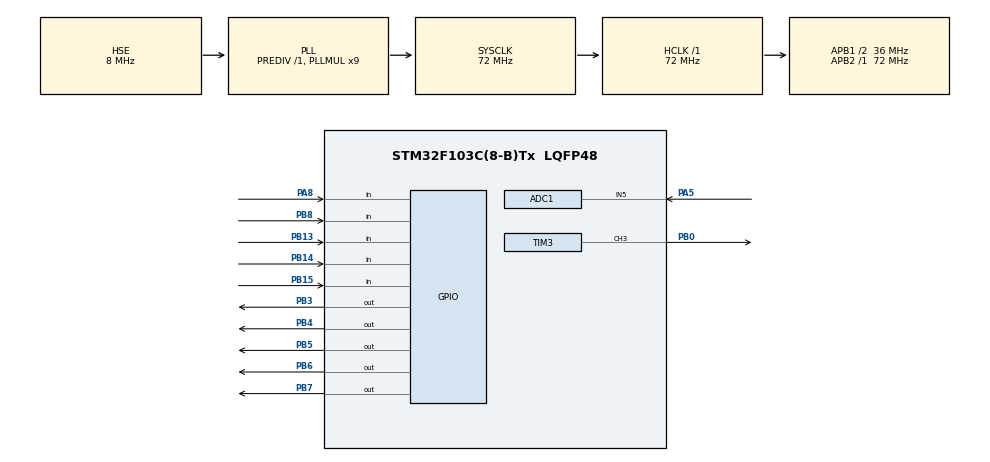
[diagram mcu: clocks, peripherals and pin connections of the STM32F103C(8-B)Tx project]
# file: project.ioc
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ADC1.Channel-0\#ChannelRegularConversion=ADC_CHANNEL_5
ADC1.ContinuousConvMode=ENABLE
ADC1.NbrOfConversionFlag=1
ADC1.Rank-0\#ChannelRegularConversion=1
ADC1.SamplingTime-0\#ChannelRegularConversion=ADC_SAMPLETIME_1CYCLE_5
ADC1.master=1
Mcu.Family=STM32F1
Mcu.Name=STM32F103C(8-B)Tx
Mcu.Package=LQFP48
NVIC.ADC1_2_IRQn=true\:0\:1\:false\:false\:true\:true\:true\:true
NVIC.PriorityGroup=NVIC_PRIORITYGROUP_2
NVIC.RCC_IRQn=true\:0\:0\:false\:false\:true\:true\:false\:true
NVIC.TIM1_UP_IRQn=true\:1\:0\:true\:false\:true\:true\:true\:true
NVIC.TIM2_IRQn=true\:2\:0\:true\:false\:true\:true\:true\:true
PA13.Mode=Serial_Wire
PA13.Signal=SYS_JTMS-SWDIO
PA14.Mode=Serial_Wire
PA14.Signal=SYS_JTCK-SWCLK
PA5.Signal=ADCx_IN5
PA8.GPIO_PuPd=GPIO_PULLUP
PA8.Signal=GPIO_Input
PB0.Signal=S_TIM3_CH3
PB13.GPIO_PuPd=GPIO_PULLUP
PB13.Signal=GPIO_Input
PB14.GPIO_PuPd=GPIO_PULLUP
PB14.Signal=GPIO_Input
PB15.GPIO_PuPd=GPIO_PULLUP
PB15.Signal=GPIO_Input
PB3.GPIO_PuPd=GPIO_PULLUP
PB3.PinState=GPIO_PIN_SET
PB3.Signal=GPIO_Output
PB4.PinState=GPIO_PIN_SET
PB4.Signal=GPIO_Output
PB5.GPIO_PuPd=GPIO_PULLUP
PB5.PinState=GPIO_PIN_SET
PB5.Signal=GPIO_Output
PB6.PinState=GPIO_PIN_SET
PB6.Signal=GPIO_Output
PB7.GPIO_PuPd=GPIO_PULLUP
PB7.PinState=GPIO_PIN_SET
PB7.Signal=GPIO_Output
PB8.GPIO_PuPd=GPIO_PULLUP
PB8.Signal=GPIO_Input
PD0-OSC_IN.Mode=HSE-External-Oscillator
PD0-OSC_IN.Signal=RCC_OSC_IN
PD1-OSC_OUT.Mode=HSE-External-Oscillator
PD1-OSC_OUT.Signal=RCC_OSC_OUT
ProjectManager.HeapSize=0x200
ProjectManager.StackSize=0x400
ProjectManager.TargetToolchain=MDK-ARM V5.32
RCC.ADCPresc=RCC_ADCPCLK2_DIV6
RCC.AHBFreq_Value=72000000
RCC.APB1CLKDivider=RCC_HCLK_DIV2
RCC.APB1Freq_Value=36000000
RCC.APB1TimFreq_Value=72000000
RCC.APB2Freq_Value=72000000
RCC.APB2TimFreq_Value=72000000
RCC.HCLKFreq_Value=72000000
RCC.PLLMUL=RCC_PLL_MUL9
RCC.PLLSourceVirtual=RCC_PLLSOURCE_HSE
RCC.SYSCLKFreq_VALUE=72000000
RCC.SYSCLKSource=RCC_SYSCLKSOURCE_PLLCLK
RCC.USBFreq_Value=72000000
SH.ADCx_IN5.0=ADC1_IN5,IN5
SH.S_TIM3_CH3.0=TIM3_CH3,PWM Generation3 CH3
TIM1.Period=10000-1
TIM1.Prescaler=720-1
TIM2.Period=10000-1
TIM2.Prescaler=7200-1
TIM3.Channel-PWM\ Generation3\ CH3=TIM_CHANNEL_3
TIM3.Period=1000-1
TIM3.Prescaler=72-1
VP_TIM1_VS_ClockSourceINT.Mode=Internal
VP_TIM2_VS_ClockSourceINT.Mode=Internal
board=custom

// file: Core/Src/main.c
/* USER CODE BEGIN Header */
/**
  ******************************************************************************
  * @file           : main.c
  * @brief          : Main program body
  ******************************************************************************
  * @attention
  *
  * Copyright (c) 2024 STMicroelectronics.
  * All rights reserved.
  *
  * This software is licensed under terms that can be found in the LICENSE file
  * in the root directory of this software component.
  * If no LICENSE file comes with this software, it is provided AS-IS.
  *
  ******************************************************************************
  */
/* USER CODE END Header */
#include "main.h"
#include "adc.h"
#include "tim.h"
#include "gpio.h"

/* USER CODE BEGIN Includes */
#include "function.h"

/* USER CODE END Includes */

/* USER CODE BEGIN PD */
uint16_t count;
extern float timer2;
/* USER CODE END PD */

void SystemClock_Config(void);

int main(void)
{

  /* MCU Configuration--------------------------------------------------------*/

  /* Reset of all peripherals, Initializes the Flash interface and the Systick. */
  HAL_Init();

  /* Configure the system clock */
  SystemClock_Config();

  /* Initialize all configured peripherals */
  MX_GPIO_Init();
  MX_ADC1_Init();
  MX_TIM1_Init();
  MX_TIM3_Init();
  MX_TIM2_Init();
  /* USER CODE BEGIN 2 */
	HAL_TIM_PWM_Start(&htim3,TIM_CHANNEL_3);
	HAL_TIM_Base_Start_IT(&htim2);

	start_led();

	init_18b20();

//	initial_arr();

  /* USER CODE END 2 */

  /* Infinite loop */
  /* USER CODE BEGIN WHILE */

  while (1)
  {

		start_pt100();

	//	if(count==20){
		if(timer2==1){
			HAL_TIM_Base_Stop_IT(&htim2);
			disp();//每隔1s显示数据
		  timer2=0;
			HAL_TIM_Base_Start_IT(&htim2);
		//	count=0;
		}
		key_scan();
		//HAL_Delay(50);
//		count+=1;

    /* USER CODE END WHILE */

  }
}

void SystemClock_Config(void)
{
  RCC_OscInitTypeDef RCC_OscInitStruct = {0};
  RCC_ClkInitTypeDef RCC_ClkInitStruct = {0};
  RCC_PeriphCLKInitTypeDef PeriphClkInit = {0};

  /** Initializes the RCC Oscillators according to the specified parameters
  * in the RCC_OscInitTypeDef structure.
  */
  RCC_OscInitStruct.OscillatorType = RCC_OSCILLATORTYPE_HSE;
  RCC_OscInitStruct.HSEState = RCC_HSE_ON;
  RCC_OscInitStruct.HSEPredivValue = RCC_HSE_PREDIV_DIV1;
  RCC_OscInitStruct.HSIState = RCC_HSI_ON;
  RCC_OscInitStruct.PLL.PLLState = RCC_PLL_ON;
  RCC_OscInitStruct.PLL.PLLSource = RCC_PLLSOURCE_HSE;
  RCC_OscInitStruct.PLL.PLLMUL = RCC_PLL_MUL9;
  if (HAL_RCC_OscConfig(&RCC_OscInitStruct) != HAL_OK)
  {
    Error_Handler();
  }

  /** Initializes the CPU, AHB and APB buses clocks
  */
  RCC_ClkInitStruct.ClockType = RCC_CLOCKTYPE_HCLK|RCC_CLOCKTYPE_SYSCLK
                              |RCC_CLOCKTYPE_PCLK1|RCC_CLOCKTYPE_PCLK2;
  RCC_ClkInitStruct.SYSCLKSource = RCC_SYSCLKSOURCE_PLLCLK;
  RCC_ClkInitStruct.AHBCLKDivider = RCC_SYSCLK_DIV1;
  RCC_ClkInitStruct.APB1CLKDivider = RCC_HCLK_DIV2;
  RCC_ClkInitStruct.APB2CLKDivider = RCC_HCLK_DIV1;

  if (HAL_RCC_ClockConfig(&RCC_ClkInitStruct, FLASH_LATENCY_2) != HAL_OK)
  {
    Error_Handler();
  }
  PeriphClkInit.PeriphClockSelection = RCC_PERIPHCLK_ADC;
  PeriphClkInit.AdcClockSelection = RCC_ADCPCLK2_DIV6;
  if (HAL_RCCEx_PeriphCLKConfig(&PeriphClkInit) != HAL_OK)
  {
    Error_Handler();
  }
}

void Error_Handler(void)
{
  __disable_irq();
  while (1)
  {
  }
}
